# STM32L4x6_v1r1 register map
File version: 1.1
Registers are 32-bit, read-write, reset 0x0 unless marked. A register's access mark holds for its fields unless they carry their own. Offsets are from the block's base; [hi:lo] are bit positions; {n}, {i} and the like mark numbered series.

## PWR — Power control
Base 0x40007000
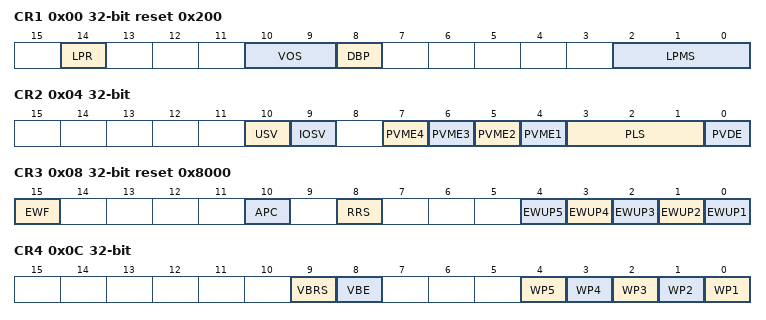
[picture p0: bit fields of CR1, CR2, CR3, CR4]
0x00 CR1 reset 0x200 — Power control register 1
  [14] LPR — Low-power run
  [10:9] VOS — Voltage scaling range selection
  [8] DBP — Disable backup domain write protection
  [2:0] LPMS — Low-power mode selection
0x04 CR2 — Power control register 2
  [10] USV — VDDUSB USB supply valid
  [9] IOSV — VDDIO2 Independent I/Os supply valid
  [7] PVME4 — Peripheral voltage monitoring 4 enable: VDDA vs. 2.2V
  [6] PVME3 — Peripheral voltage monitoring 3 enable: VDDA vs. 1.62V
  [5] PVME2 — Peripheral voltage monitoring 2 enable: VDDIO2 vs. 0.9V
  [4] PVME1 — Peripheral voltage monitoring 1 enable: VDDUSB vs. 1.2V
  [3:1] PLS — Power voltage detector level selection
  [0] PVDE — Power voltage detector enable
0x08 CR3 reset 0x8000 — Power control register 3
  [15] EWF — Enable internal wakeup line
  [10] APC — Apply pull-up and pull-down configuration
  [8] RRS — SRAM2 retention in Standby mode
  [n-1] EWUP{n} (n=1..5) — Enable Wakeup pin WKUP{n}
0x0C CR4 — Power control register 4
  [9] VBRS — VBAT battery charging resistor selection
  [8] VBE — VBAT battery charging enable
  [n-1] WP{n} (n=1..5) — Wakeup pin WKUP{n} polarity
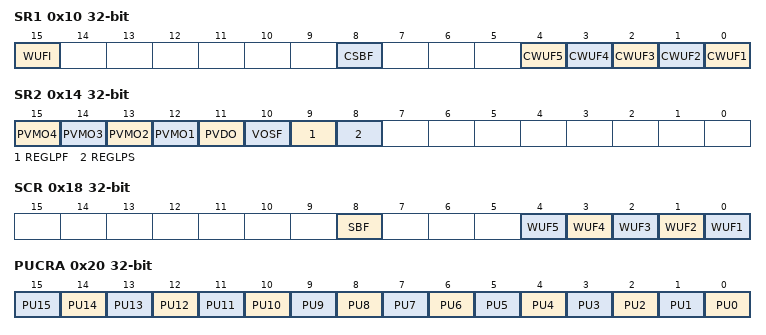
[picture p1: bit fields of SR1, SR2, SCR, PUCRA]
0x10 SR1 ro — Power status register 1
  [15] WUFI — Wakeup flag internal
  [8] CSBF — Standby flag
  [n-1] CWUF{n} (n=1..5) — Wakeup flag {n}
0x14 SR2 ro — Power status register 2
  [15] PVMO4 — Peripheral voltage monitoring output: VDDA vs. 2.2 V
  [14] PVMO3 — Peripheral voltage monitoring output: VDDA vs. 1.62 V
  [13] PVMO2 — Peripheral voltage monitoring output: VDDIO2 vs. 0.9 V
  [12] PVMO1 — Peripheral voltage monitoring output: VDDUSB vs. 1.2 V
  [11] PVDO — Power voltage detector output
  [10] VOSF — Voltage scaling flag
  [9] REGLPF — Low-power regulator flag
  [8] REGLPS — Low-power regulator started
0x18 SCR wo — Power status clear register
  [8] SBF — Clear standby flag
  [n-1] WUF{n} (n=1..5) — Clear wakeup flag {n}
0x20 PUCRA — Power Port A pull-up control register
  [n] PU{n} (n=0..15) — Port A pull-up bit y (y=0..15)
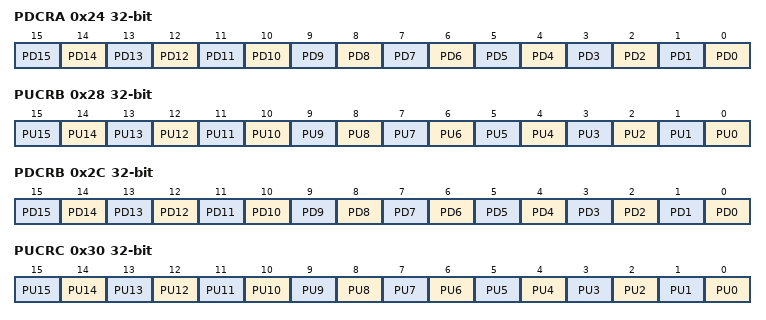
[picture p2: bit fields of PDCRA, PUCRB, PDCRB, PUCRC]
0x24 PDCRA — Power Port A pull-down control register
  [n] PD{n} (n=0..15) — Port A pull-down bit y (y=0..15)
0x28 PUCRB — Power Port B pull-up control register
  [n] PU{n} (n=0..15) — Port B pull-up bit y (y=0..15)
0x2C PDCRB — Power Port B pull-down control register
  [n] PD{n} (n=0..15) — Port B pull-down bit y (y=0..15)
0x30 PUCRC — Power Port C pull-up control register
  [n] PU{n} (n=0..15) — Port C pull-up bit y (y=0..15)
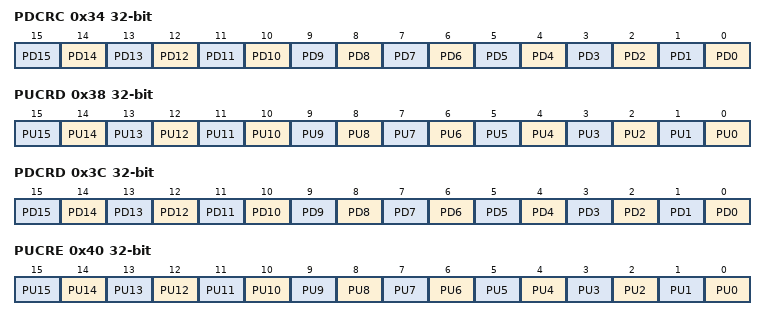
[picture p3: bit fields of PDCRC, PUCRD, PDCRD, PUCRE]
0x34 PDCRC — Power Port C pull-down control register
  [n] PD{n} (n=0..15) — Port C pull-down bit y (y=0..15)
0x38 PUCRD — Power Port D pull-up control register
  [n] PU{n} (n=0..15) — Port D pull-up bit y (y=0..15)
0x3C PDCRD — Power Port D pull-down control register
  [n] PD{n} (n=0..15) — Port D pull-down bit y (y=0..15)
0x40 PUCRE — Power Port E pull-up control register
  [n] PU{n} (n=0..15) — Port E pull-up bit y (y=0..15)
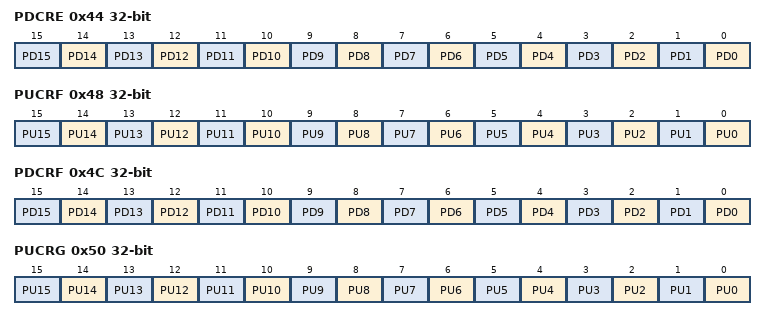
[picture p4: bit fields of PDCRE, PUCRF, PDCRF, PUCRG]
0x44 PDCRE — Power Port E pull-down control register
  [n] PD{n} (n=0..15) — Port E pull-down bit y (y=0..15)
0x48 PUCRF — Power Port F pull-up control register
  [n] PU{n} (n=0..15) — Port F pull-up bit y (y=0..15)
0x4C PDCRF — Power Port F pull-down control register
  [n] PD{n} (n=0..15) — Port F pull-down bit y (y=0..15)
0x50 PUCRG — Power Port G pull-up control register
  [n] PU{n} (n=0..15) — Port G pull-up bit y (y=0..15)
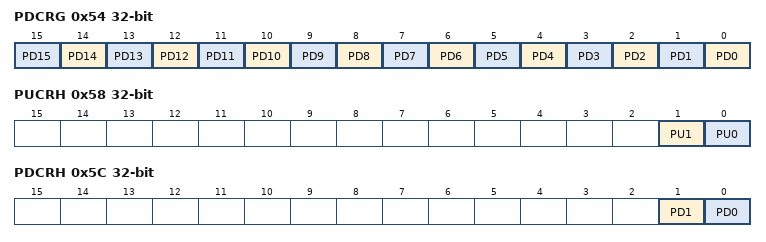
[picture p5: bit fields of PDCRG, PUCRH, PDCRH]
0x54 PDCRG — Power Port G pull-down control register
  [n] PD{n} (n=0..15) — Port G pull-down bit y (y=0..15)
0x58 PUCRH — Power Port H pull-up control register
  [1] PU1 — Port H pull-up bit y (y=0..1)
  [0] PU0 — Port H pull-up bit y (y=0..1)
0x5C PDCRH — Power Port H pull-down control register
  [1] PD1 — Port H pull-down bit y (y=0..1)
  [0] PD0 — Port H pull-down bit y (y=0..1)

## SYSCFG — System configuration controller
Base 0x40010000
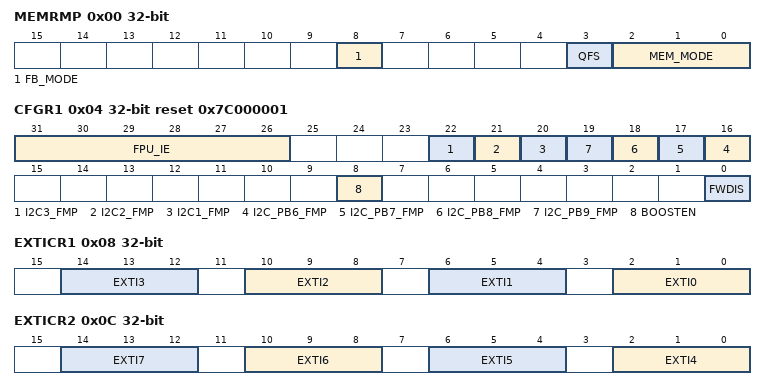
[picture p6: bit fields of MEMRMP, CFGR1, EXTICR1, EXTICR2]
0x00 MEMRMP — memory remap register
  [8] FB_MODE — Flash Bank mode selection
  [3] QFS — QUADSPI memory mapping swap
  [2:0] MEM_MODE — Memory mapping selection
0x04 CFGR1 reset 0x7C000001 — configuration register 1
  [31:26] FPU_IE — Floating Point Unit interrupts enable bits
  [22] I2C3_FMP — I2C3 Fast-mode Plus driving capability activation
  [21] I2C2_FMP — I2C2 Fast-mode Plus driving capability activation
  [20] I2C1_FMP — I2C1 Fast-mode Plus driving capability activation
  [n+10] I2C_PB{n}_FMP (n=6..9) — Fast-mode Plus (Fm+) driving capability activation on PB{n}
  [8] BOOSTEN — I/O analog switch voltage booster enable
  [0] FWDIS — Firewall disable
0x08 EXTICR1 — external interrupt configuration register 1
  [4n+2:4n] EXTI{n} (n=0..3) — EXTI {n} configuration bits
0x0C EXTICR2 — external interrupt configuration register 2
  [4n-14:4n-16] EXTI{n} (n=4..7) — EXTI {n} configuration bits
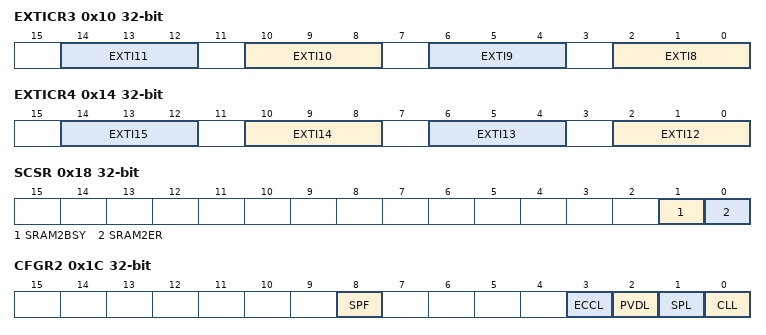
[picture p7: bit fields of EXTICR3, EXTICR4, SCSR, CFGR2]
0x10 EXTICR3 — external interrupt configuration register 3
  [4n-30:4n-32] EXTI{n} (n=8..11) — EXTI {n} configuration bits
0x14 EXTICR4 — external interrupt configuration register 4
  [4n-46:4n-48] EXTI{n} (n=12..15) — EXTI{n} configuration bits
0x18 SCSR access per field
  [1] SRAM2BSY ro — SRAM2 busy by erase operation
  [0] SRAM2ER rw — SRAM2 Erase
0x1C CFGR2 access per field
  [8] SPF rw — SRAM2 parity error flag
  [3] ECCL wo — ECC Lock
  [2] PVDL wo — PVD lock enable bit
  [1] SPL wo — SRAM2 parity lock bit
  [0] CLL wo — Cortex-M4 LOCKUP (Hardfault) output enable bit
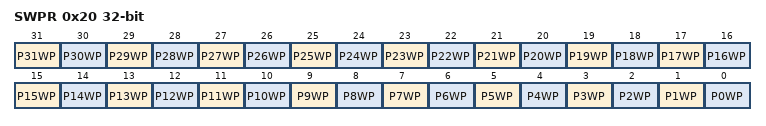
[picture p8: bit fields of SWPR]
0x20 SWPR wo
  [31] P31WP — SRAM2 page 31 write protection
  [n] P{n}WP (n=0..30)
0x24 SKR wo
  [7:0] KEY — SRAM2 write protection key for software erase
